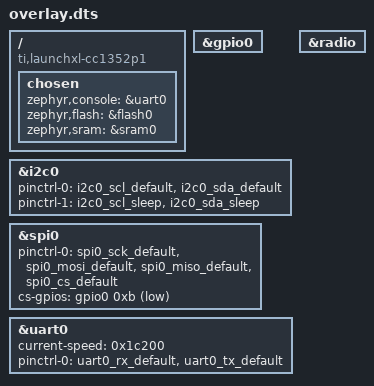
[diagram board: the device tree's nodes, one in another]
/ {
	compatible = "ti,launchxl-cc1352p1";
	chosen {
		zephyr,console = &uart0;
		zephyr,flash = &flash0;
		zephyr,sram = &sram0;
	};
};
&gpio0{
	status = "okay";
};
&i2c0{
	status = "okay";
	pinctrl-0 = < &i2c0_scl_default &i2c0_sda_default >;
	pinctrl-1 = < &i2c0_scl_sleep &i2c0_sda_sleep >;
	pinctrl-names = "default", "sleep";
};
&radio{
	status = "okay";
};
&spi0{
	status = "okay";
	pinctrl-0 = < &spi0_sck_default &spi0_mosi_default &spi0_miso_default &spi0_cs_default >;
	pinctrl-names = "default";
	cs-gpios = < &gpio0 0xb 0x1 >;
};
&uart0{
	status = "okay";
	current-speed = < 0x1c200 >;
	pinctrl-0 = < &uart0_rx_default &uart0_tx_default >;
	pinctrl-names = "default";
};
